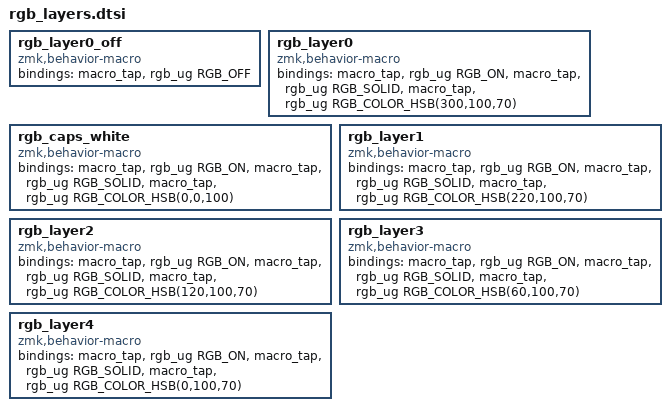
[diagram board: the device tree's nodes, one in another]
                /* Layer 0: spento */
        rgb_layer0_off: rgb_layer0_off {
            compatible = "zmk,behavior-macro";
            #binding-cells = <0>;
            bindings = <&macro_tap &rgb_ug RGB_OFF>;
        };

                /* Layer 0: magenta */
        rgb_layer0: rgb_layer0 {
            compatible = "zmk,behavior-macro";
            #binding-cells = <0>;
            bindings = <&macro_tap &rgb_ug RGB_ON>, <&macro_tap &rgb_ug RGB_SOLID>, <&macro_tap &rgb_ug RGB_COLOR_HSB(300,100,70)>;
        };

                /* Caps: bianco */
        rgb_caps_white: rgb_caps_white {
            compatible = "zmk,behavior-macro";
            #binding-cells = <0>;
            bindings = <&macro_tap &rgb_ug RGB_ON>, <&macro_tap &rgb_ug RGB_SOLID>, <&macro_tap &rgb_ug RGB_COLOR_HSB(0,0,100)>;
        };

                /* Layer 1: blu */
        rgb_layer1: rgb_layer1 {
            compatible = "zmk,behavior-macro";
            #binding-cells = <0>;
            bindings = <&macro_tap &rgb_ug RGB_ON>, <&macro_tap &rgb_ug RGB_SOLID>, <&macro_tap &rgb_ug RGB_COLOR_HSB(220,100,70)>;
        };

                /* Layer 2: verde */
        rgb_layer2: rgb_layer2 {
            compatible = "zmk,behavior-macro";
            #binding-cells = <0>;
            bindings = <&macro_tap &rgb_ug RGB_ON>, <&macro_tap &rgb_ug RGB_SOLID>, <&macro_tap &rgb_ug RGB_COLOR_HSB(120,100,70)>;
        };

                /* Layer 3: giallo */
        rgb_layer3: rgb_layer3 {
            compatible = "zmk,behavior-macro";
            #binding-cells = <0>;
            bindings = <&macro_tap &rgb_ug RGB_ON>, <&macro_tap &rgb_ug RGB_SOLID>, <&macro_tap &rgb_ug RGB_COLOR_HSB(60,100,70)>;
        };

                /* Layer 4: rosso */
        rgb_layer4: rgb_layer4 {
            compatible = "zmk,behavior-macro";
            #binding-cells = <0>;
            bindings = <&macro_tap &rgb_ug RGB_ON>, <&macro_tap &rgb_ug RGB_SOLID>, <&macro_tap &rgb_ug RGB_COLOR_HSB(0,100,70)>;
        };
